AUTOSAR XML (schema 3-2-1)
package /test/test2_swc
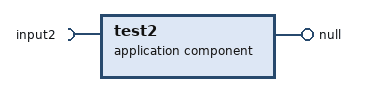
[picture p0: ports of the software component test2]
  application software component type test2
    require port input2
    provide port null
  internal behavior test2Behavior: compontent=test2
    runnable new: can-be-invoked-concurrently=true
  swc implementation test2Implementation: behavior=test2Behavior
